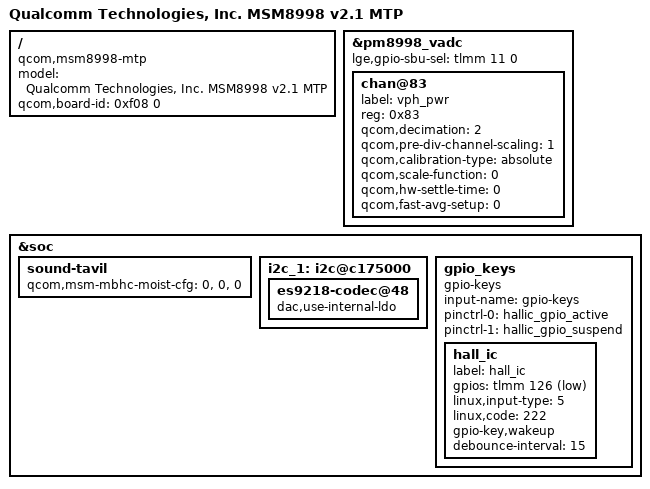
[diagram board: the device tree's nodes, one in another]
/* Copyright (c) 2016, The Linux Foundation. All rights reserved.
 *
 * This program is free software; you can redistribute it and/or modify
 * it under the terms of the GNU General Public License version 2 and
 * only version 2 as published by the Free Software Foundation.
 *
 * This program is distributed in the hope that it will be useful,
 * but WITHOUT ANY WARRANTY; without even the implied warranty of
 * MERCHANTABILITY or FITNESS FOR A PARTICULAR PURPOSE.  See the
 * GNU General Public License for more details.
 */


/dts-v1/;

#include "../../../qcom/msm8998-v2.1.dtsi"
#include "msm8998-joan_kddi_jp.dtsi"

/ {
	model = "Qualcomm Technologies, Inc. MSM8998 v2.1 MTP";
	compatible = "qcom,msm8998-mtp", "qcom,msm8998", "qcom,mtp";
	qcom,board-id = <0xf08 0>;
};

&pm8998_vadc {
	lge,gpio-sbu-sel = <&tlmm 11 0>;
	chan@83 {
		label = "vph_pwr";
		reg = <0x83>;
		qcom,decimation = <2>;
		qcom,pre-div-channel-scaling = <1>;
		qcom,calibration-type = "absolute";
		qcom,scale-function = <0>;
		qcom,hw-settle-time = <0>;
		qcom,fast-avg-setup = <0>;
    };
};

&soc {
	sound-tavil {
		qcom,msm-mbhc-moist-cfg = <0>, <0>, <0>;
	};
};

&soc {
    i2c_1: i2c@c175000 {
        es9218-codec@48 {
            dac,use-internal-ldo;
        };
    };
};

/* Hall IC */
&soc {
        gpio_keys {
                compatible = "gpio-keys";
                input-name = "gpio-keys";

                pinctrl-names = "tlmm_gpio_key_active","tlmm_gpio_key_suspend";
                pinctrl-0 = <&hallic_gpio_active>;
                pinctrl-1 = <&hallic_gpio_suspend>;

                hall_ic {
                        label = "hall_ic";
                        gpios = <&tlmm 126 0x1>;
                        linux,input-type = <5>;
                        linux,code = <222>;
                        gpio-key,wakeup;
                        debounce-interval = <15>;
                };
        };
};
